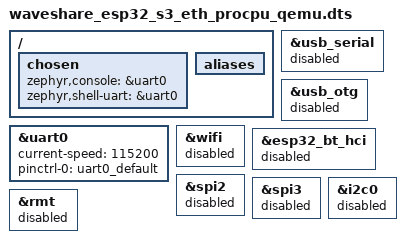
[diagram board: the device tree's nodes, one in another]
/*
 * Copyright (c) 2026 Richard Osterloh <richard.osterloh@gmail.com>
 *
 * SPDX-License-Identifier: Apache-2.0
 *
 * QEMU variant: disable the peripherals Espressif QEMU does not model.
 * See boards/espressif/common/qemu.rst for the feature matrix.
 */

#include "waveshare_esp32_s3_eth_procpu.dts"

/ {
	chosen {
		/* USB Serial/JTAG is not emulated, so the console moves to
		 * UART0 (GPIO43/44). On real hardware those pins are on the
		 * module but not brought out to the USB-C port.
		 */
		zephyr,console = &uart0;
		zephyr,shell-uart = &uart0;
		/delete-property/ zephyr,bt-hci;
	};

	aliases {
		/delete-property/ led-strip;
		/delete-property/ sw0;
		/delete-property/ sdhc0;
	};

	/delete-node/ ws2812;
	/delete-node/ buttons;
};

&uart0 {
	status = "okay";
	current-speed = <115200>;
	pinctrl-0 = <&uart0_default>;
	pinctrl-names = "default";
};

&usb_serial {
	status = "disabled";
};

&usb_otg {
	status = "disabled";
};

&wifi {
	status = "disabled";
};

&esp32_bt_hci {
	status = "disabled";
};

/* General-purpose SPI is not emulated, so the onboard W5500 and the
 * SPI-mode microSD slot go with it.
 */
&spi2 {
	status = "disabled";
};

&spi3 {
	status = "disabled";
};

&i2c0 {
	status = "disabled";
};

&rmt {
	status = "disabled";
};
